VERSION ""

NS_ :

BS_:

BU_:

BO_ 3221225472 VECTOR__INDEPENDENT_SIG_MSG: 0 Vector__XXX
 SG_ LR_WSpeed : 0|16@0+ (0.01,-100) [0|2000] "kmph" Vector__XXX
 SG_ RR_WSpeed : 0|16@0+ (0.01,-100) [0|2000] "kmph" Vector__XXX
 SG_ RF_WSpeed : 0|16@0+ (0.01,-100) [0|2000] "kmph" Vector__XXX
 SG_ LF_WSpeed : 0|16@0+ (0.01,-100) [0|2000] "kmph" Vector__XXX

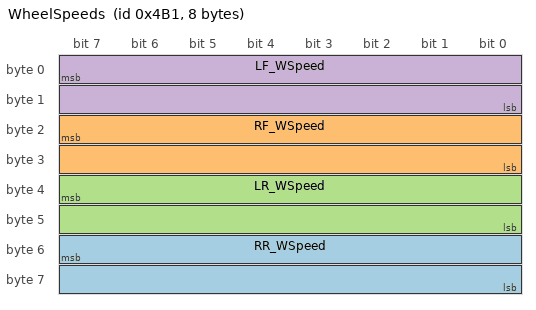
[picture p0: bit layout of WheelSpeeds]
BO_ 1201 WheelSpeeds: 8 Vector__XXX
 SG_ RR_WSpeed : 55|16@0+ (0.01,-100) [0|2000] "kmph" Vector__XXX
 SG_ RF_WSpeed : 23|16@0+ (0.01,-100) [0|2000] "kmph" Vector__XXX
 SG_ LR_WSpeed : 39|16@0+ (0.01,-100) [0|2000] "kmph" Vector__XXX
 SG_ LF_WSpeed : 7|16@0+ (0.01,-100) [0|2000] "kmph" Vector__XXX

BO_ 513 VehicleData: 8 Vector__XXX
 SG_ Engine_Speed : 7|16@0+ (0.2632,0) [0|8000] "" Vector__XXX
 SG_ Accel_Pos : 48|8@1+ (0.5,0) [0|100] "%" Vector__XXX

CM_ BO_ 3221225472 "This is a message for not used signals, created by Vector CANdb++ DBC OLE DB Provider.";
